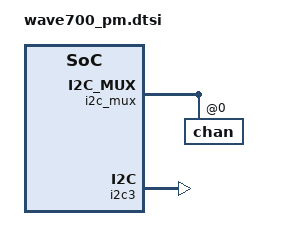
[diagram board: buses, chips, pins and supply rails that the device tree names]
// SPDX-License-Identifier: GPL-2.0
/*
 * Copyright (C) 2023 MaxLinear, Inc.
 */

&i2c_mux {
	status = "okay";

	chan@0 {
		#address-cells = <1>;
		#size-cells = <0>;
		reg = <0>;

		hwmon@6d {
			compatible = "ltc2945";
			reg = <0x6d>;
			ltc2945,resistor = <3>; /* the unit is mohm */
			rail-name = "WAV7_PWR_0V8\n";
		};
		hwmon@6e {
			compatible = "ltc2945";
			reg = <0x6e>;
			ltc2945,resistor = <10>; /* the unit is mohm */
			rail-name = "WAV7_PWR_1V2\n";
		};
		hwmon@6f {
			compatible = "ltc2945";
			reg = <0x6f>;
			ltc2945,resistor = <25>; /* the unit is mohm */
			rail-name = "WAV7_PWR_1V8\n";
		};
	};
};

&i2c3 {
	status = "okay";
};
